# psoc6_01 register map
Vendor: Cypress Semiconductor; Series: psoc6_01; File version: 1.0
CPU: CM4 r0p1, little endian, MPU, FPU, VTOR, 3 interrupt priority bits
Registers are 32-bit, read-write, reset 0x0 unless marked. A register's access mark holds for its fields unless they carry their own. Offsets are from the block's base; [hi:lo] are bit positions; lines under a group give offsets from that group; {n}, {i} and the like mark numbered series; <NAME> marks a mode.

## BLE (part 3 of 5) — Bluetooth Low Energy Subsystem
Base 0x403C0000
0x1000 BLELL group — Bluetooth Low Energy Link Layer
  0xC8 TIM_COUNTER_L ro — Reference Clock
    [15:0] TIM_REF_CLOCK — 16-bit internal reference clock. The clock is a free run-ning clock, incremented by a 0.625ms periodic pulse. It is used as a reference clock to derive all the timing required as per protocol.
  0xCC WAKEUP_CONFIG_EXTD — Wakeup configuration extended
    [4:0] DSM_LF_OFFSET — Number of 'LF slots' before the wake up instant before which the hardware needs to exit from deep sleep mode. The LF slot is of 62.5us period. This is a onetime configuration field, which is used every time hardware does an auto-wakeup before the next wakeup instant. This is in addition to the LF slots calculated by HW window widening logic.
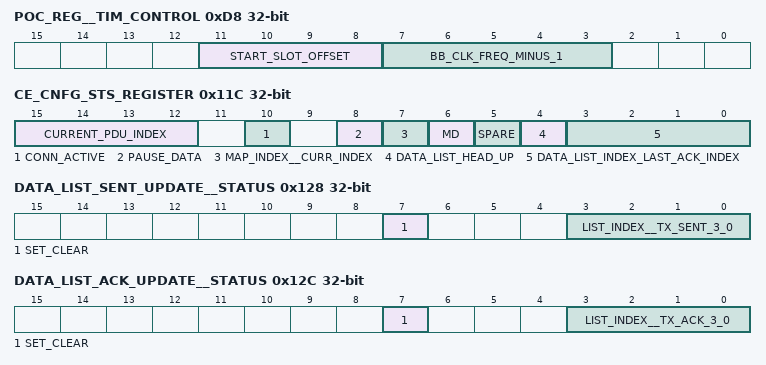
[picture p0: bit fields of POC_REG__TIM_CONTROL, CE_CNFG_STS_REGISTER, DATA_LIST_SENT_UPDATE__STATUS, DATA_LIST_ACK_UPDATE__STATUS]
  0xD8 POC_REG__TIM_CONTROL — BLE Time Control
    [11:8] START_SLOT_OFFSET — LLH clock configuration. The start of slot signal is offset by this value. If value is 0, the start of slot signal is generated at the 625us. The offset value is in terms of us.
    [7:3] BB_CLK_FREQ_MINUS_1 — LLH clock configuration. The clock frequency of the clock input to this design is configured in this register. This is used to derive a 1MHz clock.
  0xE0 ADV_TX_DATA_FIFO — Advertising data transmit FIFO. Access ADVCH_TX_FIFO.
    [15:0] ADV_TX_DATA — IO mapped FIFO of depth 16 (2 byte wide), to store ADV data of maximum length 31 bytes for transmitting. Firmware writes consecutive words by writing to the same address location. Note: ADV_TX_DATA_FIFO and ADV_SCN_RSP_TX_FIFO shares same physical FIFO of depth 32. 16 locations for each FIFO are allocated. Reading this location resets the FIFO pointer.
  0xE8 ADV_SCN_RSP_TX_FIFO — Advertising scan response data transmit FIFO. Access ADVCH_TX_FIFO.
    [15:0] SCAN_RSP_DATA — IO mapped FIFO of depth 16 (2 byte wide), to store scan response data of maximum length 31 bytes for transmitting. Firmware writes consecutive words by writing to the same location. Note: ADV_TX_DATA_FIFO and ADV_SCN_RSP_TX_FIFO shares same physical FIFO of depth 32. 16 locations for each FIFO are allocated. Reading this location resets the FIFO pointer.
  0xF8 INIT_SCN_ADV_RX_FIFO ro — advertising scan response data receive data FIFO. Access ADVRX_FIFO.
    [15:0] ADV_SCAN_RSP_RX_DATA — IO mapped FIFO of depth 64, to store ADV and SCAN_RSP header and payload received by the scanner. The RSSI value at the time of reception of this packet is also stored. Firmware reads from the same address to read out consecutive words of data. Note: The 16 bit header is first loaded to the advertise channel data receive FIFO followed by the payload data and then 16 bit RSSI.
  0x100 CONN_INTERVAL — Connection Interval
    [15:0] CONNECTION_INTERVAL — The value configured in this register determines the spacing be-tween the connection events. This shall be a multiple of 1.25 ms in the range of 7.5 ms to 4.0 s.
  0x104 SUP_TIMEOUT — Supervision timeout
    [15:0] SUPERVISION_TIMEOUT — This field defines the maximum time between two received Data packet PDUs before the connection is considered lost. This shall be a multiple of 10 ms in the range of 100 ms to 32.0 s and it shall be larger than (1+connSlaveLatency)*connInterval.
  0x108 SLAVE_LATENCY
    [15:0] SLAVE_LATENCY — The value configured in this field defines the number of consecutive connection events that the slave device is not required to listen for master. The value of connSlaveLatency should not cause a Supervision Timeout. This shall be an integer in the range of 0 to ((connSupervision Timeout/connInterval)-1). connSlaveLatency shall also be less than 500.
  0x10C CE_LENGTH — Connection event length
    [15:0] CONNECTION_EVENT_LENGTH — This field defines the length of Connection event. This value is derived from the CE length HCI parameters received from the host. This determines the number of master transmit slots in a connection event, subject to either of the MD bits being set. If both MD bits are set to 0, this has no effect. Units: 625us Note: The connection event length as specified by the CE_LENGTH shall not exceed CONN_INTERVAL - 1.25 ms. The CE-length parameter, according to the Bluetooth specification, is the length of the connection event. Take an example to illustrate this scenario: Assume a connection with interval = 100ms. that the application has put allowed 20ms of CE-length. Here, the CE-length can be upto 100ms (100ms - 150us to be exact). If the connection is maintained for 5 minutes, there could be 10*60*5 = 3000 connection-intervals. The CE-length need not be maintained constant during all the 3000 connection events. Here are the typical cases that determine the value of CE-length: (1) No data packets exchanged. we are just maintaining time and frequency synchronization. In this case, only a packet pair will be exchanged every connection interval. Here, CE-length = 1. (2) Average of 10 packets to be sent per connection event. We can pump data in multiple ways here: 2.1: Send data at uniform rate : In this case, the CE-length will be enough to accommodate 10 packets, which will take about 7ms. As this is less than application enforced limit of 20ms, we can comfortably push all the 10 data packets in this connection interval. So data will be pumped to the other BT device at the same rate as is received from my application. 2.2: Can send data in bursts. Assume that we accumulate data for 1 second and pump out at the end of 1 second(this is not done by our Bluetooth stack, the application needs to buffer the data). So, at 10th connection interval, we have 100 packets accumulated. We are now ready to pump this data. 100 packets take about 70 ms. This is above the application enforced 20ms. So, the hardware can pump data that can fill up 20ms. The remaining data will be deferred to the next connection interval. So, in this case, you would see a CE-length spread over time like this (Per connection interval): 0,0,0,0,0,0,0,0,0,0, 20,20,20,10,0,0,0,0,0,0, 20,20,20,10,0,0,0,0,0,0, 20,20,20,10,0,0,0,0,0,0, and so on. (3) We are receiving data at the same rate as in (2). This case is to honor data sent by the other BT-device by giving it more time in the current connection interval. In (2) and (3) you will see non-empty packets either transmitted or received. We can also utilize the CE-length for different reasons: (4) A transaction is in progress, and we are expecting a response packet very soon. In this case, we may be exchanging only empty packets now, and in the next few packet-pairs. In this case, you will the CE-length to be large, and a non-empty packet may not be exchanged in all the slots.
  0x110 PDU_ACCESS_ADDR_L_REGISTER — Access address (lower)
    [15:0] PDU_ACCESS_ADDRESS_LOWER_BITS — This field defines the lower 16 bits of the access address for each Link layer connection between any two devices.
  0x114 PDU_ACCESS_ADDR_H_REGISTER — Access address (upper)
    [15:0] PDU_ACCESS_ADDRESS_HIGHER_BITS — This field defines the higher 16 bits of the access address for each Link layer connection between any two devices.
  0x118 CONN_CE_INSTANT — Connection event instant
    [15:0] CE_INSTANT — This is the value of the free running Connection Event counter when the new parameters of 'connection update' and/or 'Channel map update' will be effective. Range : 0x0000 to 0xFFFF
  0x11C CE_CNFG_STS_REGISTER — connection configuration & status register
    [15:12] CURRENT_PDU_INDEX ro — The index of the transmit packet buffer that is currently in transmission/waiting for transmission.
    [10] CONN_ACTIVE ro — This bit is '1' whenever the connection is active.
    [8] PAUSE_DATA — Pause data. 1 - pause data, 0 - do not pause. The current_pdu_index in hardware does not move to next in-dex until pause_data is cleared. But if the SENT bit is set for the current_pdu_index as which pause is set, data will be sent out
    [7] MAP_INDEX__CURR_INDEX — Written by firmware to select the map index to be used by hardware for this connection. 1 - use channel map register set 1. 0 - use channel map register set 0. When firmware reads this field, it returns the current map index being used in hardware.
    [6] MD — MD bit set to '1' indicates device has more data to be sent.
    [5] SPARE — This bit is unused
    [4] DATA_LIST_HEAD_UP — Update the first packet buffer index ready for transmis-sion to start/resume data transfer after a pause. The bit must be toggled every time the firmware needs to indicate the start/resume. This requires a read modify write operation.
    [3:0] DATA_LIST_INDEX_LAST_ACK_INDEX — Data list index for start/resume. This field must be valid along with data_list_head_up and indicate the transmit packet buffer index at which the data is loaded. The default number of buffers in the IP is 5,but may be customized for a customer. The buffers are in-dexed 0 to 4. Hardware will start the next data transmission from the index indicated by this field.
  0x120 NEXT_CE_INSTANT ro reset 0xFFFF — Next connection event instant
    [15:0] NEXT_CE_INSTANT — 16-bit internal reference clock value at which the next connection event will occur on a connection. The connection index register must be programmed with index of the connection, before reading the register. The reset value is 0x0000. After reset deassertion, then the very next clock, the value assigned to the registers is 0xFFFF.
  0x124 CONN_CE_COUNTER ro — connection event counter
    [15:0] CONNECTION_EVENT_COUNTER — This is the free running counter, connEventCounter as defined by Bluetooth spec. Firmware will read the instantaneous Event counter from this register, during connection update and channel map update procedure. Firmware will use this value to calculate the instant from which the new parameters (for connection update and channel map update) will be effective.
  0x128 DATA_LIST_SENT_UPDATE__STATUS — data list sent update and status
    [7] SET_CLEAR wo — Write: Used to set the SENT bit in hardware for the selected packet buffer. 1 - packet queued When firmware has a packet to send, firmware first loads the next available packet buffer. Then the hardware SENT bit is set by writing 1 to this bit field along with the list_index field that identified the buffer index. This indicates that a packet has been queued in the data buffer for sending. This packet is now ready to be transmitted. The SENT bit in hardware is cleared by hardware only when it has received an acknowledgement from the remote device. Firmware typically does not clear the bit. However, It only clears the bit on its own if it needs to 'flush' a packet from the buffer, without waiting to receive acknowledgement from the remote device, firmware clears BIT7 along with the list_index specified.
    [3:0] LIST_INDEX__TX_SENT_3_0 — Write:Indicates the buffer index for which the SENT bit is being updated by firmware. The default number of buffers in the IP is 4. The index range is 0-3. Read: Reads TX_SENT[3:0]. The bits in this field indicate the status of the SENT bit in the hard-ware for each packet buffer. The bit values are 1 - queued 0 - no packet / packet ack received by hardware Example1: If the read value is : 0x03, then packets in buffer 0 and buffer 1 are in the queue to be transmitted. All the other FIFOs are empty or hardware has cleared them after receiving acknowledgement. NOTE: The SENT status bit and ACK status bit have to be taken together to understand the meaning of packet status. The table below describes how the two bits are sequentially updated by either hardware/firmware to complete one data transmission. SENT ACK Description 0 0 Buffer is empty. No packet is queued in the buffer 1 0 Packet is queued by firmware. 1 1 Packet is transmitted by hardware. Hardware is waiting for acknowledgement. 0 1 Hardware has received ACK. Firmware has not yet processed the ACK. 0 0 Firmware has processed the ack. The buffer is again empty.
  0x12C DATA_LIST_ACK_UPDATE__STATUS — data list ack update and status
    [7] SET_CLEAR wo — Write: Firmware uses the field to clear and ACK bit in the hardware to indicate that the acknowledgement for the transmit packet has been received and processed by firmware. Firmware clears the ACK bit in the hardware by writing in this register only after the acknowledgement is processed successfully by firmware. For clearing ack for a packet transmitted in fifo-index : '3', firm-ware will write '3' in the 'list-index' field and set this bit (BIT7) to 0. This is the indication that the corresponding packet buffer identi-fied by List-Index is cleared of previous transmission and can be re-used for another packet from now on. The ACK bit in hardware is set by hardware when it has success-fully transmitted a packet.
    [3:0] LIST_INDEX__TX_ACK_3_0 — Write: Indicates the buffer index for which the ACK bit is being updated by firmware. The default number of buffers in the IP is 5. The index range is 0-4. Read: Reads TX_ACK[3:0] If a particular bit is set, then the packet in the selected buffer has been transmitted (at least once) by the hardware and hardware is waiting for acknowledgement. Example1 : If the read value is : 0x03, then packets in FIFO-0 and FIFO-1 are acknowledged by the remote device. These acknowledgements are pending to be processed by firmware. Example2 : If the read value is : 0x02, then packet FIFO-1 is acknowledged by the remote device. This acknowledgement is pending to be processed by firmware. NOTE: The SENT status bit and ACK status bit have to be taken together to understand the meaning of packet status. The table below describes how the two bits are sequentially updated by either hardware/firmware to complete one data transmission. SENT ACK Description 0 0 Buffer is empty. No packet is queued in the buffer 1 0 Packet is queued by firmware. 1 1 Packet is transmitted by hardware. Hardware is waiting for acknowledgement. 0 1 Hardware has received ACK. Firmware has not yet processed the ACK. 0 0 Firmware has processed the ack. The buffer is again empty.
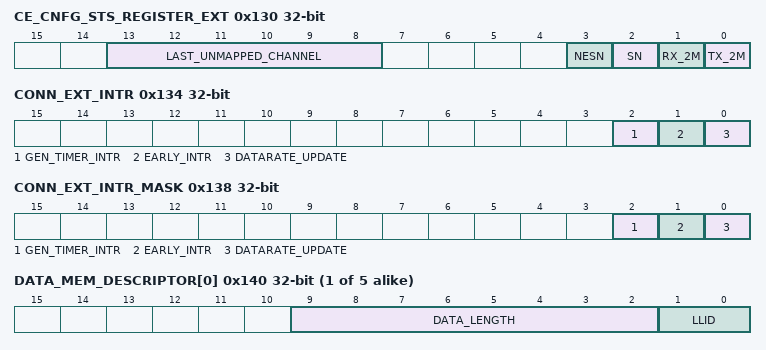
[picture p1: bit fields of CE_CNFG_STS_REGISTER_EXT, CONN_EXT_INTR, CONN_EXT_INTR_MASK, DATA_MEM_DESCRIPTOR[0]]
  0x130 CE_CNFG_STS_REGISTER_EXT — connection configuration & status register
    [13:8] LAST_UNMAPPED_CHANNEL — Last unmapped channel for next scheduled connection index
    [3] NESN — Next Sequence number for next scheduled connection index
    [2] SN — Sequence number for next scheduled connection index
    [1] RX_2M — receiving on 2M
    [0] TX_2M — transmittion on 2M
  0x134 CONN_EXT_INTR — Connection extended interrupt status and Clear register
    [2] GEN_TIMER_INTR — If this bit is set it indicates that the generic timer (PDU response timer reconfigured in MMMS mode) has expired If this bit is written with 1, it clears the interrupt status bit
    [1] EARLY_INTR — For master this bit is set on start_ce For Slave this bit is set on slave_timer_adj
    [0] DATARATE_UPDATE — If this bit is set it indicates that the data rate is updated If this bit is written with 1, it clears the interrupt status bit
  0x138 CONN_EXT_INTR_MASK — Connection Extended Interrupt mask
    [2] GEN_TIMER_INTR — Generic timer (PDU response timer reconfigured in MMMS mode) expiry interrupt
    [1] EARLY_INTR — If this bit is set connection early interrupt is enabled.
    [0] DATARATE_UPDATE — If this bit is set connection data rate update interrupt is enabled.
  {0x140+4j} DATA_MEM_DESCRIPTOR[{j}] (j=0..4) — Data buffer descriptor 0 to 4
    [9:2] DATA_LENGTH — This field indicates the length of the data packet. Bits [9:7] are valid only if DLE is set. Range 0x00 to 0xFF.
    [1:0] LLID
  0x160 WINDOW_WIDEN_INTVL reset 0xA — Window widen for interval
    [11:0] WINDOW_WIDEN_INTVL — This value defines the increased listening time for the slave. The window widening shall be smaller than ((connInterval/2)-T_IFS us) This value is calculated by firmware based on the drift, the connec-tion interval value. The value is the unit widening value for one con-nection interval duration. In case of slave latency, this value is accu-mulated till the next anchor point at which the slave will listen.
  0x164 WINDOW_WIDEN_WINOFF reset 0xA — Window widen for offset
    [11:0] WINDOW_WIDEN_WINOFF — This field stores the additional number of microseconds the slave must extend its listening window to listen for a master packet. This value is calculated based on the window offset value. This is used at connection setup directly. During connection setup, this value is added with window_widen_intvl register value to calculate the win-dow widening size.
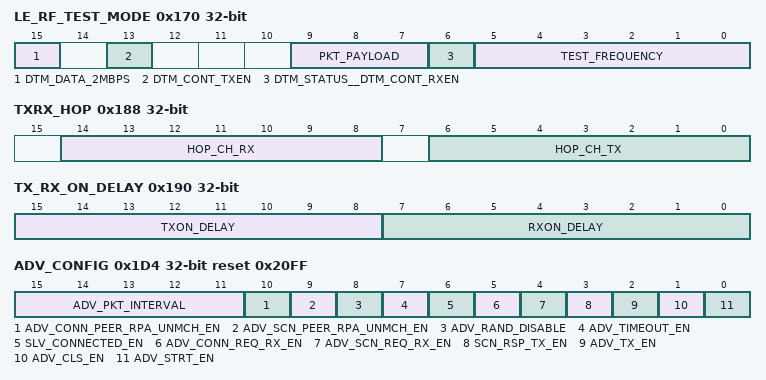
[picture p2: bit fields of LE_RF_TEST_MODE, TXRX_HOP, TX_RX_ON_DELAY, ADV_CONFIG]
  0x170 LE_RF_TEST_MODE — Direct Test Mode control
    [15] DTM_DATA_2MBPS — 0: DTM run at 1M bps data rate 1: DTM run at 2M bps data rate
    [13] DTM_CONT_TXEN — 0: DTM run at normal DTMTX burst mode 1: DTM run at continuous TX DTM mode
    [9:7] PKT_PAYLOAD
    [6] DTM_STATUS__DTM_CONT_RXEN — This bit is overloaded. The read operation returns the staus of the DTM 1 - DTM test ON 0 - DTM test OFF The write operation contrls the DTM RX mode 0: DTM run at normal DTMRX burst mode 1: DTM run at continuous RX DTM mode
    [5:0] TEST_FREQUENCY — N = (F - 2402) / 2 Range: 0x00 - 0x27. Frequency Range : 2402 MHz to 2480 MHz
  0x174 DTM_RX_PKT_COUNT ro — Direct Test Mode receive packet count
    [15:0] RX_PACKET_COUNT — Number of packets received in receive test mode.
  0x178 LE_RF_TEST_MODE_EXT — Direct Test Mode control
    [7:0] DTM_PACKET_LENGTH — DTM TX packet length. Bits [7:6] are accessible onle when DLE is enabled
  0x188 TXRX_HOP ro — Channel Address register
    [14:8] HOP_CH_RX — Receive channel index. Channel index on which previous packet is received.
    [6:0] HOP_CH_TX — Transmit channel index. Channel index on which previous packet is transmitted.
  0x190 TX_RX_ON_DELAY — Transmit/Receive data delay
    [15:8] TXON_DELAY — Transmit delay - Delay from start of transmit to transmission of first bit on air. It is used to control the T_IFS. The delay is in resolution of 1 microsecond.
    [7:0] RXON_DELAY — Receive delay - Delay from start of receive to expected first bit of receive packet at the controller. Used to control the turn on time of radio to optimize on power. The delay is in resolution of 1 microsecond.
  0x1A8 ADV_ACCADDR_L reset 0xBED6 — ADV packet access code low word
    [15:0] ADV_ACCADDR_L — Lower 16 bit of ADV packet access code
  0x1AC ADV_ACCADDR_H reset 0x8E89 — ADV packet access code high word
    [15:0] ADV_ACCADDR_H — higher 16 bit of ADV packet access code
  0x1B0 ADV_CH_TX_POWER_LVL_LS — Advertising channel transmit power setting
    [15:0] ADV_TRANSMIT_POWER_LVL_LS — When LL_CONFIG.TX_PA_PWR_LVL_TYPE is 1, this field represents the Advertising channel transmit power setting Least Significant 16 bits. When LL_CONFIG.TX_PA_PWR_LVL_TYPE is 0, the LS 4 bits represents the Advertising channel transmit power code 4 bits.
  0x1B4 ADV_CH_TX_POWER_LVL_MS — Advertising channel transmit power setting extension
    [1:0] ADV_TRANSMIT_POWER_LVL_MS — Advertising channel transmit power setting Most Significant 2 bits.
  0x1B8 CONN_CH_TX_POWER_LVL_LS — Connection channel transmit power setting
    [15:0] CONNCH_TRANSMIT_POWER_LVL_LS — When LL_CONFIG.TX_PA_PWR_LVL_TYPE is 1, this field represents the Connection channel transmit power setting Least Significant 16 bits. When LL_CONFIG.TX_PA_PWR_LVL_TYPE is 0, the LS 4 bits represents the Connection channel transmit power code 4 bits.
  0x1BC CONN_CH_TX_POWER_LVL_MS — Connection channel transmit power setting extension
    [1:0] CONNCH_TRANSMIT_POWER_LVL_MS — Connection channel transmit power setting Most Significant 2 bits.
  0x1C0 DEV_PUB_ADDR_L reset 0x3412 — Device public address lower register
    [15:0] DEV_PUB_ADDR_L — Lower 16 bit of 48-bit public address of the device.
  0x1C4 DEV_PUB_ADDR_M reset 0x56 — Device public address middle register
    [15:0] DEV_PUB_ADDR_M — Middle 16 bit of 48-bit public address of the device.
  0x1C8 DEV_PUB_ADDR_H — Device public address higher register
    [15:0] DEV_PUB_ADDR_H — Higher 16 bit of 48-bit public address of the device.
  0x1D0 OFFSET_TO_FIRST_INSTANT reset 0x6
    [15:0] OFFSET_TO_FIRST_EVENT — The offset w.r.t the internal reference clock at which instant the first event occurs. This register will give flexibility to the firmware to position the con-nection at a desired point with respect to the internal free running clock. It is optional to be updated by firmware. This is not updated in the current firmware.
  0x1D4 ADV_CONFIG reset 0x20FF — Advertiser configuration register
    [15:11] ADV_PKT_INTERVAL — Time between the beginning of two consecutive advertising PDU's. Time = N * 0.625 msec Time Range: <=10msec.
    [10] ADV_CONN_PEER_RPA_UNMCH_EN — Enable connect request packet received with peer device address unmatched interrupt. This bit is valid only if PRIV_1_2 and PRIV_1_2_ADV are set.
    [9] ADV_SCN_PEER_RPA_UNMCH_EN — Enable scan request packet received with peer device address unmatched interrupt. This bit is valid only if PRIV_1_2 PRIV_1_2 and PRIV_1_2_ADV are set.
    [8] ADV_RAND_DISABLE — Disable randomization of adv interval. When disabled, interval is same as programmed in adv_interval register.
    [7] ADV_TIMEOUT_EN — Enable adv_timeout interrupt. Applicable in adv_direct_ind advertising.
    [6] SLV_CONNECTED_EN — Enable slave connected interrupt.
    [5] ADV_CONN_REQ_RX_EN — Enable connect request packet received interrupt.
    [4] ADV_SCN_REQ_RX_EN — Enable scan request packet received interrupt.
    [3] SCN_RSP_TX_EN — Enable scan response packet transmitted interrupt.
    [2] ADV_TX_EN — Enable adv packet transmitted interrupt.
    [1] ADV_CLS_EN — Enable advertising event stop interrupt.
    [0] ADV_STRT_EN — Enable advertising event start interrupt.
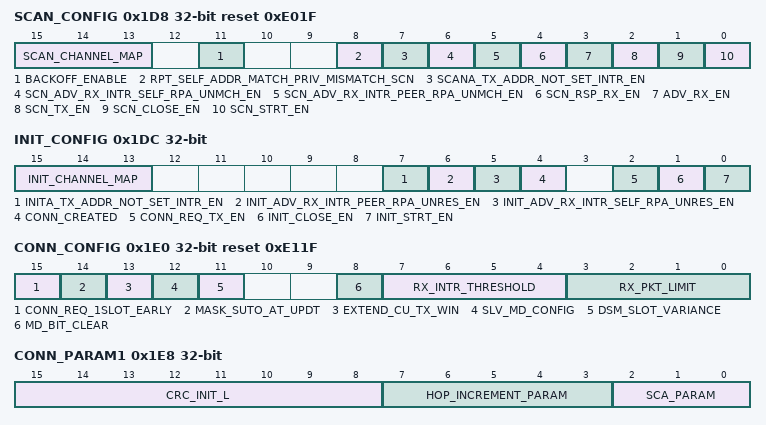
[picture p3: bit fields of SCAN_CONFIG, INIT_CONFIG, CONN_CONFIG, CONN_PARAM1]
  0x1D8 SCAN_CONFIG reset 0xE01F — Scan configuration register
    [15:13] SCAN_CHANNEL_MAP — Advertising channels that are enabled for scanning operation. Bit 15: setting 1 - enables channel 39 for use. Bit 14: setting 1 - enables channel 38 for use. Bit 13: setting 1 - enables channel 37 for use.
    [11] BACKOFF_ENABLE — Enable random backoff feature in scanner. 1 - enable 0 - disable
    [8] RPT_SELF_ADDR_MATCH_PRIV_MISMATCH_SCN — This bit controls the SCAN engine behavior when an self address match occurs but a privacy mismatch occurs 0 - The packet is aborted 1 - The packet is received and reported to the Link Layer firmware This bit is valid only if PRIV_1_2 and PRIV_1_2_SCAN are set.
    [7] SCANA_TX_ADDR_NOT_SET_INTR_EN — Enable SCANA RPA TX not set interrupt. This bit is valid only if PRIV_1_2 and PRIV_1_2_SCAN are set.
    [6] SCN_ADV_RX_INTR_SELF_RPA_UNMCH_EN — Enable ADV self address unmatched interrupt. This bit is valid only if PRIV_1_2 PRIV_1_2 and PRIV_1_2_SCAN are set.
    [5] SCN_ADV_RX_INTR_PEER_RPA_UNMCH_EN — Enable ADV peer address unmatched interrupt. This bit is valid only if PRIV_1_2 PRIV_1_2 and PRIV_1_2_SCAN are set.
    [4] SCN_RSP_RX_EN — Enable scan_rsp packet received interrupt .
    [3] ADV_RX_EN — Enable adv packet received interrupt .
    [2] SCN_TX_EN — Enable scan request packet transmitted interrupt.
    [1] SCN_CLOSE_EN — Enable scan event close interrupt.
    [0] SCN_STRT_EN — Enable scan event start interrupt.
  0x1DC INIT_CONFIG — Initiator configuration register
    [15:13] INIT_CHANNEL_MAP — Advertising channels that are enabled for initiator scanning operation. Bit 15: setting 1 - enables channel 39 for use. Bit 14: setting 1 - enables channel 38 for use. Bit 13: setting 1 - enables channel 37 for use.
    [7] INITA_TX_ADDR_NOT_SET_INTR_EN — Enable INITA RPA TX not set interrupt. This bit is valid only if PRIV_1_2 and PRIV_1_2_INIT are set.
    [6] INIT_ADV_RX_INTR_PEER_RPA_UNRES_EN — Enable ADV peer address RPA unresolved interrupt. This bit is valid only if PRIV_1_2 and PRIV_1_2_INIT are set.
    [5] INIT_ADV_RX_INTR_SELF_RPA_UNRES_EN — Enable ADV self address RPA unresolved interrupt. This bit is valid only if PRIV_1_2 and PRIV_1_2_INIT are set.
    [4] CONN_CREATED — Enable master connection created interrupt
    [2] CONN_REQ_TX_EN — Enables connection request packet transmission start interrupt.
    [1] INIT_CLOSE_EN — Enable Initiator event close interrupt.
    [0] INIT_STRT_EN — Enable Initiator event start interrupt.
  0x1E0 CONN_CONFIG reset 0xE11F — Connection configuration register
    [15] CONN_REQ_1SLOT_EARLY — This bit is used to enable extension of the Conn Request to arbiter to 1 slot early. When enabled the request length is 2 slots. 1 - Enable 0 - Disable
    [14] MASK_SUTO_AT_UPDT — This bit is used to enable/disable masking of internal hardware supervision timeout trigger when switching from old connection parameters to new parameters. 1 - Enable 0 - Disable
    [13] EXTEND_CU_TX_WIN — This bit is used to enable/disable extending the additional rx window on slave side during connection update in event of packet miss at the update instant. 1 - Enable 0 - Disable
    [12] SLV_MD_CONFIG — This bit is set to configure the MD bit control when IUT is in slave role. 1 - MD bit will be decided on packet pending status 0 - MD bit will be decided on packet queued in next buffer status This bit has effect only when 'CONN_CONFIG.md_bit_ctr' bit is not set .
    [11] DSM_SLOT_VARIANCE — This bit configures the DSM slot counting mode. 0 - The DSM slot count variance with respect to actual time is less than 1 slot 1 - The DSM slot count variance with respect to actual time is more than 1 slot &less that 2 slots
    [8] MD_BIT_CLEAR — This register field indicates whether the MD (More Data) bit needs to be controlled by 'software' or, 'hardware and soft-ware logic combined'. 1 - MD bit is exclusively controlled by software, ie based on status of CE_CNFG_STS_REGISTER[6] - md bit. 0 - MD Bit in the transmitted pdu is controlled by software and hardware logic. MD bit is set in transmitted packet, only if the software has set the md bit in CE_CNFG_STS_REGISTER[6] and either of the following conditions is true, a) If there are packets queued for transmission. b) If there is an acknowledgement awaited from the remote side for the packet transmitted.
    [7:4] RX_INTR_THRESHOLD — This register field allows setting a threshold for the packet received interrupt to the firmware. For example if the value programmed is 0x2 - then HW will generate interrupt only on receiving the second packet. In any case if the received number of packets in a conn event is less than the threshold or there are still packets (less than threshold) pending in the Rx FIFO, HW will generate the interrupt at the ce_close. Min value possible is 1. Max value depends on the Rx FIFO capacity.
    [3:0] RX_PKT_LIMIT — Defines a limit for the number of Rx packets that can be re-ceived by the LLH. Default maximum value is 0xF.Minimum value shall be '1' or no packet will be stored in the Rx FIFO.
  0x1E8 CONN_PARAM1 — Connection parameter 1
    [15:8] CRC_INIT_L — This field defines the lower byte (7:0) of the CRC initialization vector.
    [7:3] HOP_INCREMENT_PARAM — Hop increment for connection channel.
    [2:0] SCA_PARAM — Sleep Clock Accuracy
  0x1EC CONN_PARAM2 — Connection parameter 2
    [15:0] CRC_INIT_H — This field defines the upper two bytes (23:8) of the CRC initialization vector.
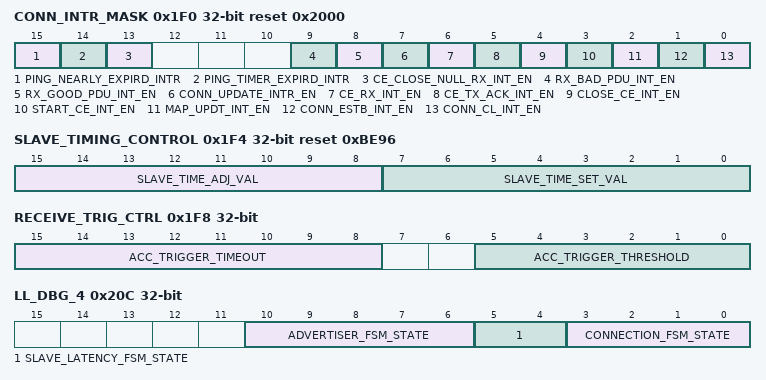
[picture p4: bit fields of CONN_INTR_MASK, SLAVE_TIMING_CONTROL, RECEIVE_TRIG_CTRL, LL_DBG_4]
  0x1F0 CONN_INTR_MASK reset 0x2000 — Connection Interrupt mask
    [15] PING_NEARLY_EXPIRD_INTR — If this bit is set ping timer nearly expired interrupt is enabled
    [14] PING_TIMER_EXPIRD_INTR — If this bit is set ping timer expired interrupt is enabled.
    [13] CE_CLOSE_NULL_RX_INT_EN — If this but us set, the RX interrupt is triggerred for an end of connection event with a null packet
    [9] RX_BAD_PDU_INT_EN — If this bit is set packet receive bad pdu interrupt is enabled. Effective only when bit 6 is set.
    [8] RX_GOOD_PDU_INT_EN — If this bit is set packet receive good pdu interrupt is enabled. Effective only when bit 6 is set.
    [7] CONN_UPDATE_INTR_EN — If this bit is set connection update interrupt is enabled.
    [6] CE_RX_INT_EN — If this bit is set interrupt is enabled for reception of packet in a connection event.
    [5] CE_TX_ACK_INT_EN — If this bit is set transmission acknowledgement interrupt is enabled: This interrupt is generated to indicate to the firmware that a non-empty packet transmitted is successfully acknowledged by the remote device. For negative acknowledgements from remote device, this interrupt indication is not generated.
    [4] CLOSE_CE_INT_EN — If this bit is set connection event closed interrupt is enabled.
    [3] START_CE_INT_EN — If this bit is set connection event start interrupt is enabled
    [2] MAP_UPDT_INT_EN — If this bit is set, channel map update interrupt is enabled.
    [1] CONN_ESTB_INT_EN — If this bit is set connection establishment interrupt is enabled.
    [0] CONN_CL_INT_EN — If this bit is set connection closed interrupt is enabled.
  0x1F4 SLAVE_TIMING_CONTROL reset 0xBE96
    [15:8] SLAVE_TIME_ADJ_VAL — Timing adjust value. The internal micro second counter is adjusted to this value whenever slave receives a good access address match at connection anchor point. This will ensure the slave gets synchronized to master timing.
    [7:0] SLAVE_TIME_SET_VAL — Programmable adjust value to the clock counter when slave is connected
  0x1F8 RECEIVE_TRIG_CTRL — Receive trigger control
    [15:8] ACC_TRIGGER_TIMEOUT — If access address match does not occur then within this time from the start of receive operation, the receive operation times out and stops. An internal counter value of 1usec resolution is continuously compared with the value programmed. Max value :0xFF
    [5:0] ACC_TRIGGER_THRESHOLD — Access address match threshold value. Number of bits of ac-cess address that should match with the expected access ad-dress to trigger an access code match. Max value : 32 (for 32-bit access address) Lower values may be programmed for bad radios or channels but care must be taken to ensure there are no 'false' matches due to reduced number of bits required to match.
  0x200 LL_DBG_1 ro — LL debug register 1
    [9:0] CONN_RX_WR_PTR — Connection receive FIFO write pointer
  0x204 LL_DBG_2 ro — LL debug register 2
    [9:0] CONN_RX_RD_PTR — Connection receive FIFO read pointer
  0x208 LL_DBG_3 ro — LL debug register 3
    [9:0] CONN_RX_WR_PTR_STORE — Connection receive FIFO stored write pointer for pointer restore
  0x20C LL_DBG_4 ro — LL debug register 4
    [10:6] ADVERTISER_FSM_STATE, [5:4] SLAVE_LATENCY_FSM_STATE, [3:0] CONNECTION_FSM_STATE
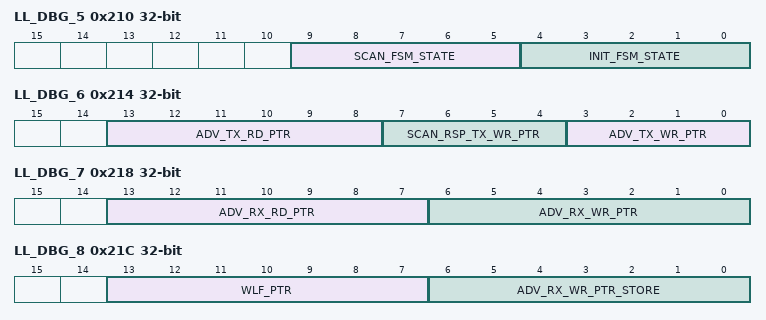
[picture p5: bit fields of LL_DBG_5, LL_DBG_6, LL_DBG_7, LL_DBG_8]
  0x210 LL_DBG_5 ro — LL debug register 5
    [9:5] SCAN_FSM_STATE — Scanner FSM state
    [4:0] INIT_FSM_STATE — Initiator FSM state
  0x214 LL_DBG_6 ro — LL debug register 6
    [13:8] ADV_TX_RD_PTR — Advertiser/ Scan Response FIFO read pointer
    [7:4] SCAN_RSP_TX_WR_PTR — Scan Response Transmit FIFO write pointer
    [3:0] ADV_TX_WR_PTR — Advertiser Transmit FIFO write pointer
  0x218 LL_DBG_7 ro — LL debug register 7
    [13:7] ADV_RX_RD_PTR — Advertiser Receive FIFO read pointer
    [6:0] ADV_RX_WR_PTR — Advertiser Receive FIFO write pointer
  0x21C LL_DBG_8 ro — LL debug register 8
    [13:7] WLF_PTR — Whitelist FIFO pointer
    [6:0] ADV_RX_WR_PTR_STORE — Advertiser Receive FIFO stored write pointer for pointer restore
  0x220 LL_DBG_9 ro reset 0x10 — LL debug register 9
    [15:0] WINDOW_WIDEN — Window Widening value in us. The reset value of this register is 0x0000. After reset de-assertion, at the first clock cycle, the value 0x0010 is assigned to the register.
  0x224 LL_DBG_10 ro — LL debug register 10
    [5:0] RF_CHANNEL_NUM — Active channel number
  0x230 PEER_ADDR_INIT_L — Lower 16 bit address of the peer device for INIT.
    [15:0] PEER_ADDR_L — Lower 16 bit of 48-bit address of the peer device. This is used only in MMMS mode The peer address registers are used for multiple purposes. The register is written by firmware to provide the peer address to be used for a hardware procedure. When firmware reads the register, it reads back peer address values updated by hardware. While device is configured as an initiator without white list filtering, the peer address specified in the peer_address field of the create connection command is programmed into this register, which is used by hard-ware procedures. While device is configured as an initiator and white list is enabled, firmware can read this register to get the address of the peer device from which connectable ADV packet was received and to which the connection is created.
  0x234 PEER_ADDR_INIT_M — Middle 16 bit address of the peer device for INIT.
    [15:0] PEER_ADDR_M — Middle 16 bit of 48-bit address of the peer device. This is used only in MMMS mode The peer address registers are used for multiple purposes. The register is written by firmware to provide the peer address to be used for a hardware procedure. When firmware reads the register, it reads back peer address values updated by hardware. While device is configured as an initiator without white list filtering, the peer address specified in the peer_address field of the create connection command is programmed into this register, which is used by hard-ware procedures. While device is configured as an initiator and white list is enabled, firmware can read this register to get the address of the peer device from which connectable ADV packet was received and to which the connection is created.
  0x238 PEER_ADDR_INIT_H — Higher 16 bit address of the peer device for INIT.
    [15:0] PEER_ADDR_H — Higher 16 bit of 48-bit address of the peer device. This is used only in MMMS mode The peer address registers are used for multiple purposes. The register is written by firmware to provide the peer address to be used for a hardware procedure. When firmware reads the register, it reads back peer address values updated by hardware. While device is configured as an initiator without white list filtering, the peer address specified in the peer_address field of the create connection command is programmed into this register, which is used by hard-ware procedures. While device is configured as an initiator and white list is enabled, firmware can read this register to get the address of the peer device from which connectable ADV packet was received and to which the connection is created.
  0x23C PEER_SEC_ADDR_ADV_L — Lower 16 bits of the secondary address of the peer device for ADV_DIR.
    [15:0] PEER_SEC_ADDR_L — Lower 16 bit of 48-bit secondary address of the peer device for ADV_DIR.
  0x240 PEER_SEC_ADDR_ADV_M — Middle 16 bits of the secondary address of the peer device for ADV_DIR.
    [15:0] PEER_SEC_ADDR_M — Middle 16 bit of 48-bit secondary address of the peer device for ADV_DIR.
  0x244 PEER_SEC_ADDR_ADV_H — Higher 16 bits of the secondary address of the peer device for ADV_DIR.
    [15:0] PEER_SEC_ADDR_H — Higher 16 bit of 48-bit secondary address of the peer device for ADV_DIR. While doing directed Advertising in device privacy mode, if the peer device has shared its IRK, then the peer device RPA is written into the PEER_ADDR registers and the peer device identity address is written into this register. If the peer device has not shared its IRK, then the peer identity address is written into the PEER_ADDR registers and this register must be cleared.
  0x248 INIT_WINDOW_TIMER_CTRL — Initiator Window NI timer control
    [0] INIT_WINDOW_OFFSET_SEL — Controls the INIT Window offset source 1 - Pick INIT Window Offset from HW calculated INIT_WINDOW_OFFSET 0 - Pick INIT Window Offset from FW loaded register
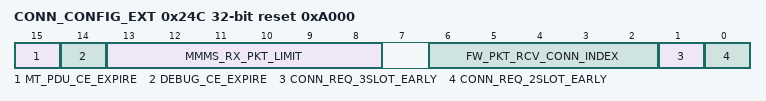
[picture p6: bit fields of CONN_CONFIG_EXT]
  0x24C CONN_CONFIG_EXT reset 0xA000 — Connection extended configuration register
    [15] MT_PDU_CE_EXPIRE — MMMS empty PDU CE expire handling control bit
    [14] DEBUG_CE_EXPIRE — MMMS CE expire control bit
    [13:8] MMMS_RX_PKT_LIMIT — Receive Packet Limit for MMMS mode. This is the RX_FIFO Limit and applies to all connections together
    [6:2] FW_PKT_RCV_CONN_INDEX — Connection Index for which the FW generates Packet Received Command. In MMMS mode, FW should write this field before giving PKT_RECEIVE_COMMAND to HW.
    [1] CONN_REQ_3SLOT_EARLY — This bit is used to enable extension of the Conn Request to arbiter to 3 slot early. When enabled the request length is 4 slots, irrespective of the status of CONN_REQ_1SLOT_EARLY & CONN_REQ_2SLOT_EARLY bits. 1 - Enable 0 - Disable
    [0] CONN_REQ_2SLOT_EARLY — This bit is used to enable extension of the Conn Request to arbiter to 2 slot early. When enabled the request length is 3 slots, irrespective of the status of CONN_REQ_1SLOT_EARLY bit. 1 - Enable 0 - Disable
  0x258 DPLL_CONFIG — DPLL & CY Correlator configuration register
    [15:0] DPLL_CORREL_CONFIG — If MXD_IF_OPTION is 0: Not used If CY_CORREL_EN is 1: [11:0] CY correl Access address compare mask for LSB 12 bits. Ideal value is 0xFFF [15:12] CY correl maximum number of allowed mismatched bits in access address. Ideal value is 0x0.
  0x260 INIT_NI_VAL — Initiator Window NI instant
    [15:0] INIT_NI_VAL — Initiator window Next Instant value used for spacing Master connections in time, to minimize connection contention. This value is in 625us slots. The read value corresponds to the hardware updated Interval value
  0x264 INIT_WINDOW_OFFSET ro — Initiator Window offset captured at conn request
    [15:0] INIT_WINDOW_NI — Initiator Window offset captured at conn request. This value is in 1.25ms slots
  0x268 INIT_WINDOW_NI_ANCHOR_PT ro — Initiator Window NI anchor point captured at conn request
    [15:0] INIT_INT_OFF_CAPT — Initiator interval offset captured at conn request. The value indicates the master connection anchor point. This value is in 625us slots
  0x3A4 CONN_UPDATE_NEW_INTERVAL — Connection update new interval
    [15:0] CONN_UPDT_INTERVAL — This register will have the new connection interval that the hardware will use after the connection update instant. Before the instant, the connection interval in the register CONN_INTERVAL will be used by hardware.
  0x3A8 CONN_UPDATE_NEW_LATENCY — Connection update new latency
    [15:0] CONN_UPDT_SLV_LATENCY — This register will have the new slave latency parameter that the hardware will use after the connection update instant. Before the instant, the connection interval in the register SLAVE_LATENCY will be used by hardware.
  0x3AC CONN_UPDATE_NEW_SUP_TO — Connection update new supervision timeout
    [15:0] CONN_UPDT_SUP_TO — This register will have the new supervision timeout that the hardware will use after the connection update instant. Before the instant, the connection interval in the register SUP_TIMEOUT will be used by hardware.
